# a34m42x register map
Vendor: ABOV Semiconductor Co., Ltd.; File version: 1.0
CPU: CM4 r0p1, little endian, MPU, FPU, VTOR, 4 interrupt priority bits
Registers are 32-bit, read-write, reset 0x0 unless marked. A register's access mark holds for its fields unless they carry their own. Offsets are from the block's base; [hi:lo] are bit positions.

## SPI — Serial Peripheral Interface Bus
Base 0x50009000
Same registers: SPI0 0x40009000, SPI1 0x40009100, SPI2 0x40009200
0x00 TDR wo — SPI n Transmit Data Register
  [16:0] TDR — Transmit Data Bit
0x00 RDR ro — SPI n Received Data Register
  [16:0] RDR — Received Data Bit
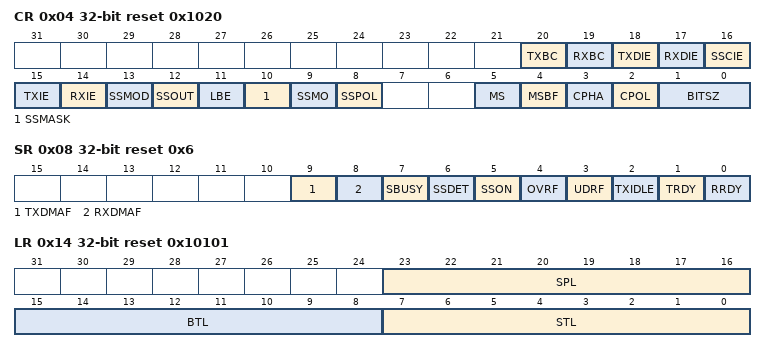
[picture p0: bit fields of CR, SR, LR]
0x04 CR reset 0x1020 — SPI Control Register
  [20] TXBC — Tx Buffer Clear Bit
  [19] RXBC — Rx Buffer Clear Bit
  [18] TXDIE — DMA Tx Complete Interrupt Enable Bit
  [17] RXDIE — DMA Rx Complete Interrupt Enable Bit
  [16] SSCIE — SS Edge Changed Interrupt Enable Bit
  [15] TXIE — Transmit Interrupt Enable Bit
  [14] RXIE — Received Interrupt Enable Bit
  [13] SSMOD — SS Auto/Manual Output Selection Bit in Master Mode
  [12] SSOUT — SS Output Signal Control Bit
  [11] LBE — Loop-back Mode Selection Bit in Master Mode
  [10] SSMASK — SS Signal Masking in Slave Mode
  [9] SSMO — SS Output Signal Selection Bit
  [8] SSPOL — SS Signal Polarity Selection Bit
  [5] MS — Master/Slave Selection Bit
  [4] MSBF — MSB/LSB Transmit Advance Selection Bit
  [3] CPHA — SPI Clock Phase Bit
  [2] CPOL — SPI Clock Polarity Bit
  [1:0] BITSZ — Transmit/Receive Bit Size Selection Bit
    0=8_BIT (Size is 8 bit); 1=9_BIT (Size is 9 bit); 2=16_BIT (Size is 16 bit); 3=17_BIT (Size is 17 bit)
0x08 SR reset 0x6 — SPI n Status Register
  [9] TXDMAF — DMA Transmit Operation Complete Flag
  [8] RXDMAF — DMA Received Operation Complete Flag
  [7] SBUSY ro — Transmit/Received Operating Flag
  [6] SSDET — SS Signal Rising or Falling Edge Detected Flag
  [5] SSON — SS Signal Status Flag
  [4] OVRF — Received Overrun Error Flag
  [3] UDRF — Transmit Underrun Error Flag
  [2] TXIDLE ro — Transmit Operating Flag
  [1] TRDY ro — Transmit Buffer Empty Flag
  [0] RRDY ro — Received Buffer Empty Flag
0x0C BR reset 0xFFFF — SPI n Baud Rate Register
  [15:0] BR — Baud Rate Setting Bit
0x10 EN — SPI n Enable Register
  [0] ENABLE — SPI Enable Bit
0x14 LR reset 0x10101 — SPI n Delay Length Register
  [23:16] SPL — SPI STOP Length Value Bit
  [15:8] BTL — SPI Burst Length Value Bit
  [7:0] STL — SPI Start Length Value Bit

## I2C — Inter-Integrated Circuit
Base 0x5000A000
Same registers: I2C0 0x4000A000, I2C1 0x4000A100
0x00 DR reset 0xFF — I2Cn Data Register
  [7:0] ICDR — The I2CnDR Transmit buffer and Receive buffer share the same I/O address with this DATA register. The Transmit Data Buffer is the destination for data written to the I2CnDR register. Reading the I2CnDR register returns the contents of the Receive Buffer.
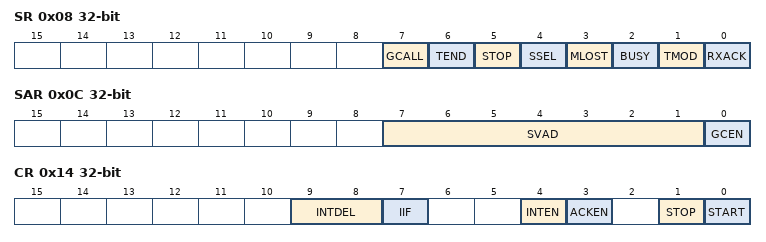
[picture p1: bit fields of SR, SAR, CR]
0x08 SR — I2Cn Status Register
  [7] GCALL — This bit has different meaning depending on whether I2C is master or slave. When I2C is a master, this bit represents whether it received AACK (address ACK) from slave.
  [6] TEND — This bit is set when 1-byte of data is transferred completely.
  [5] STOP — This bit is set when a STOP condition is detected.
  [4] SSEL — This bit is set when I2C is addressed by other master.
  [3] MLOST — This bit represents the result of bus arbitration in master mode.
  [2] BUSY — This bit reflects bus status.
  [1] TMOD ro — This bit is used to indicate whether I2C is transmitter or receiver.
  [0] RXACK — This bit shows the state of ACK signal.
0x0C SAR — I2Cn Slave Address Register
  [7:1] SVAD — These bits configure the slave address in slave mode.
  [0] GCEN — This bit decides whether I2Cn allows general call address 0 or not in I2Cn slave mode.
0x14 CR — I2Cn Control Register
  [9:8] INTDEL — between Address and Transmit data delay
    0=1_ICnSCLL (Delay = 1*ICnSCLL); 1=2_ICnSCLL (Delay = 2*ICnSCLL); 2=4_ICnSCLL (Delay = 4*ICnSCLL); 3=8_ICnSCLL (Delay = 8*ICnSCLL)
  [7] IIF ro — I2Cn Interrupt Flag bit. This bit is cleared when write any values in the I2CnST register.
  [4] INTEN — Interrupt Enable bit
  [3] ACKEN — received mode ACK allow bit
  [1] STOP — STOP Condition Generation When I2Cn is master.
  [0] START — START Condition Generation When I2Cn is master.
0x18 SCLL reset 0xFFFF — I2Cn SCL Low Period Register
  [15:0] SCLL — This register defines the low period of SCL in master mode. The base clock is PCLK and the period is calculated by the formula: tPCLK X (4 X I2CnSCLR + 2) where tPCLK is the period of PCLK.
0x1C SCLH reset 0xFFFF — I2Cn SCL High Period Register
  [15:0] SCLH — SCLH Value
0x20 SDH reset 0x7FFF — I2Cn SCL Hold Time Register
  [14:0] SDH — SDH Value

## RNG — Random Number Generator
Base 0x40000A00
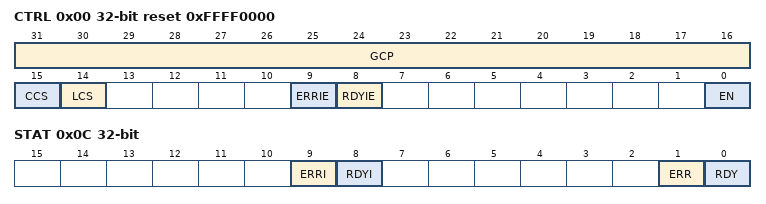
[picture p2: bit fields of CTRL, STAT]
0x00 CTRL reset 0xFFFF0000 — RNG Control Register
  [31:16] GCP — Generation Counter Parameter
  [15] CCS — CASR Clock Selection Bit
    0=RNG_OSC2; 1=HSI
  [14] LCS — LFSR Clock Selection Bit
    0=RNG_OSC1; 1=LSI (HSI)
  [9] ERRIE — Error Interrupt Enable Bit
    0=Disable interrupt; 1=Enable interrupt
  [8] RDYIE — RNGD Data Ready Interrupt Enable Bit
    0=Disable interrupt; 1=Enable interrupt
  [0] EN — RNG Start Bit
    0=STOP (RNG STOP); 1=START (RNG START)
0x04 SEED — RNG SEED Register
  [31:0] SEED — RND Seed Setting Bit
0x08 RNGD ro — RNG Random number data register
  [31:0] RNGD — Random number generation data bit
0x0C STAT — RNG Status Register
  [9] ERRI ro — Error Interrupt Flag Bit
  [8] RDYI ro — RNGD Data Ready Interrupt Flag Bit
  [1] ERR — Error Status Bit, Writing a '1' to the bit clears ERR bit or ERRI bit
  [0] RDY — RNGD Ready Status Bit, Writing a '1' to the bit clears RDYI bit

## CRC — CYCLIC REDUNDANCY CHECK AND CHECKSUM
Base 0x41002000
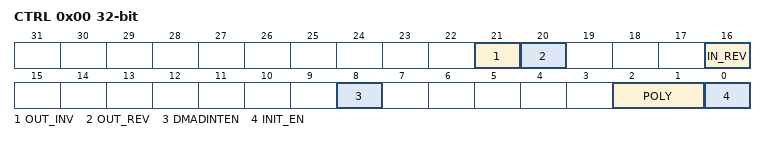
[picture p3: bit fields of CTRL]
0x00 CTRL — CRC Control Register
  [21] OUT_INV — CRC Output Data Inversion Enable bit
  [20] OUT_REV — CRC Output Data Reverse Enable Bit
  [16] IN_REV — Input Data Reverse Mode Selection Bit
  [8] DMADINTEN — DMA Done Interrupt Enable Bit
  [2:1] POLY — Polynomal Selection Bit
    0=CRC32 (0x04C1_1DB7); 1=CRC16 (0x8005); 2=CRC8 (0x07); 3=CRC7 (0x09)
  [0] INIT_EN wo — CRC Init Register Apply Bit
0x04 INIT reset 0xFFFFFFFF — CRC Init value Register
  [31:0] INIT — CRC Initial Value
0x08 IDR wo — CRC Input Data Register
  [31:0] IDR — CRC Input Data Bit
0x08 ODR ro reset 0xFFFFFFFF — CRC Output Data Register
  [31:0] ODR — CRC Output Data Bit
0x0C STAT — CRC Status Register
  [8] DMADINT — DMA Done Interrupt Flag Bit
